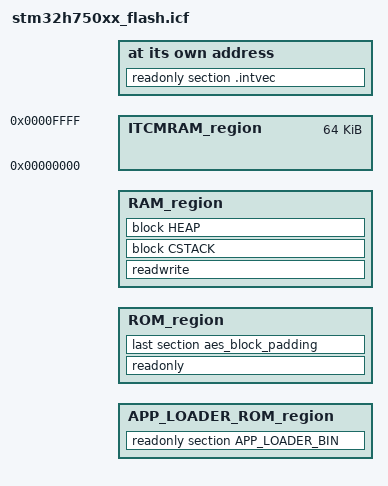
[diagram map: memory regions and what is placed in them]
/*###ICF### Set of symbols used in UserApp project ****/

define memory mem with size = 4G;

/******************************************************************************/
/*       Include of SBSFU symbols file                                        */
/*   (Project>Options>Linker>Extra Options --config_search option is used to  */
/*   specify the the directory to search for include files                    */
/******************************************************************************/
include "mapping_sbsfu.icf";
include "mapping_fwimg.icf";

/*-Specials-*/
define exported symbol __ICFEDIT_intvec_start__ = __ICFEDIT_SLOT_Active_1_start__ + 1024; /* Cortex-M7 : must be a multiple of 1024 */

/*-Memory Regions-*/
define symbol __ICFEDIT_region_ROM_start__     = __ICFEDIT_APP_LOADER_region_ROM_end__ + 1; 
define symbol __ICFEDIT_region_ROM_end__       = __ICFEDIT_SLOT_Active_1_end__;
define symbol __ICFEDIT_region_RAM_start__     = __ICFEDIT_SE_region_RAM_end__ + 1;
/* Be careful : a specific region reserved for LOADER execution from RAM starts from __ICFEDIT_APP_LOADER_region_RAM_code_start__ */
define symbol __ICFEDIT_region_RAM_end__       = __ICFEDIT_APP_LOADER_region_RAM_code_start__ - 1;
define symbol __ICFEDIT_region_ITCMRAM_start__ = 0x00000000;
define symbol __ICFEDIT_region_ITCMRAM_end__   = 0x0000FFFF;

/*-Sizes-*/
define symbol __ICFEDIT_size_cstack__ = 0x800;
define symbol __ICFEDIT_size_heap__   = 0x200;

define region APP_LOADER_ROM_region = mem:[from __ICFEDIT_APP_LOADER_region_ROM_start__   to __ICFEDIT_APP_LOADER_region_ROM_end__];
define region ROM_region      = mem:[from __ICFEDIT_region_ROM_start__   to __ICFEDIT_region_ROM_end__];
define region RAM_region      = mem:[from __ICFEDIT_region_RAM_start__   to __ICFEDIT_region_RAM_end__];
define region ITCMRAM_region  = mem:[from __ICFEDIT_region_ITCMRAM_start__ to __ICFEDIT_region_ITCMRAM_end__];

/* to make sure the binary size is a multiple of the AES block size (16 bytes) and H7 flash writing unit (32 bytes) */
define root section aes_block_padding with alignment=32
{
udata8 "Force Alignment";
pad_to 32;
};

define block CSTACK    with alignment = 8, size = __ICFEDIT_size_cstack__   { };
define block HEAP      with alignment = 8, size = __ICFEDIT_size_heap__     { };

initialize by copy { readwrite };
do not initialize  { section .noinit };

place at address mem:__ICFEDIT_intvec_start__ { readonly section .intvec };

place in APP_LOADER_ROM_region { readonly section APP_LOADER_BIN };
place in ROM_region   { readonly, last section aes_block_padding };
place in RAM_region   { readwrite,
                        block CSTACK, block HEAP };
